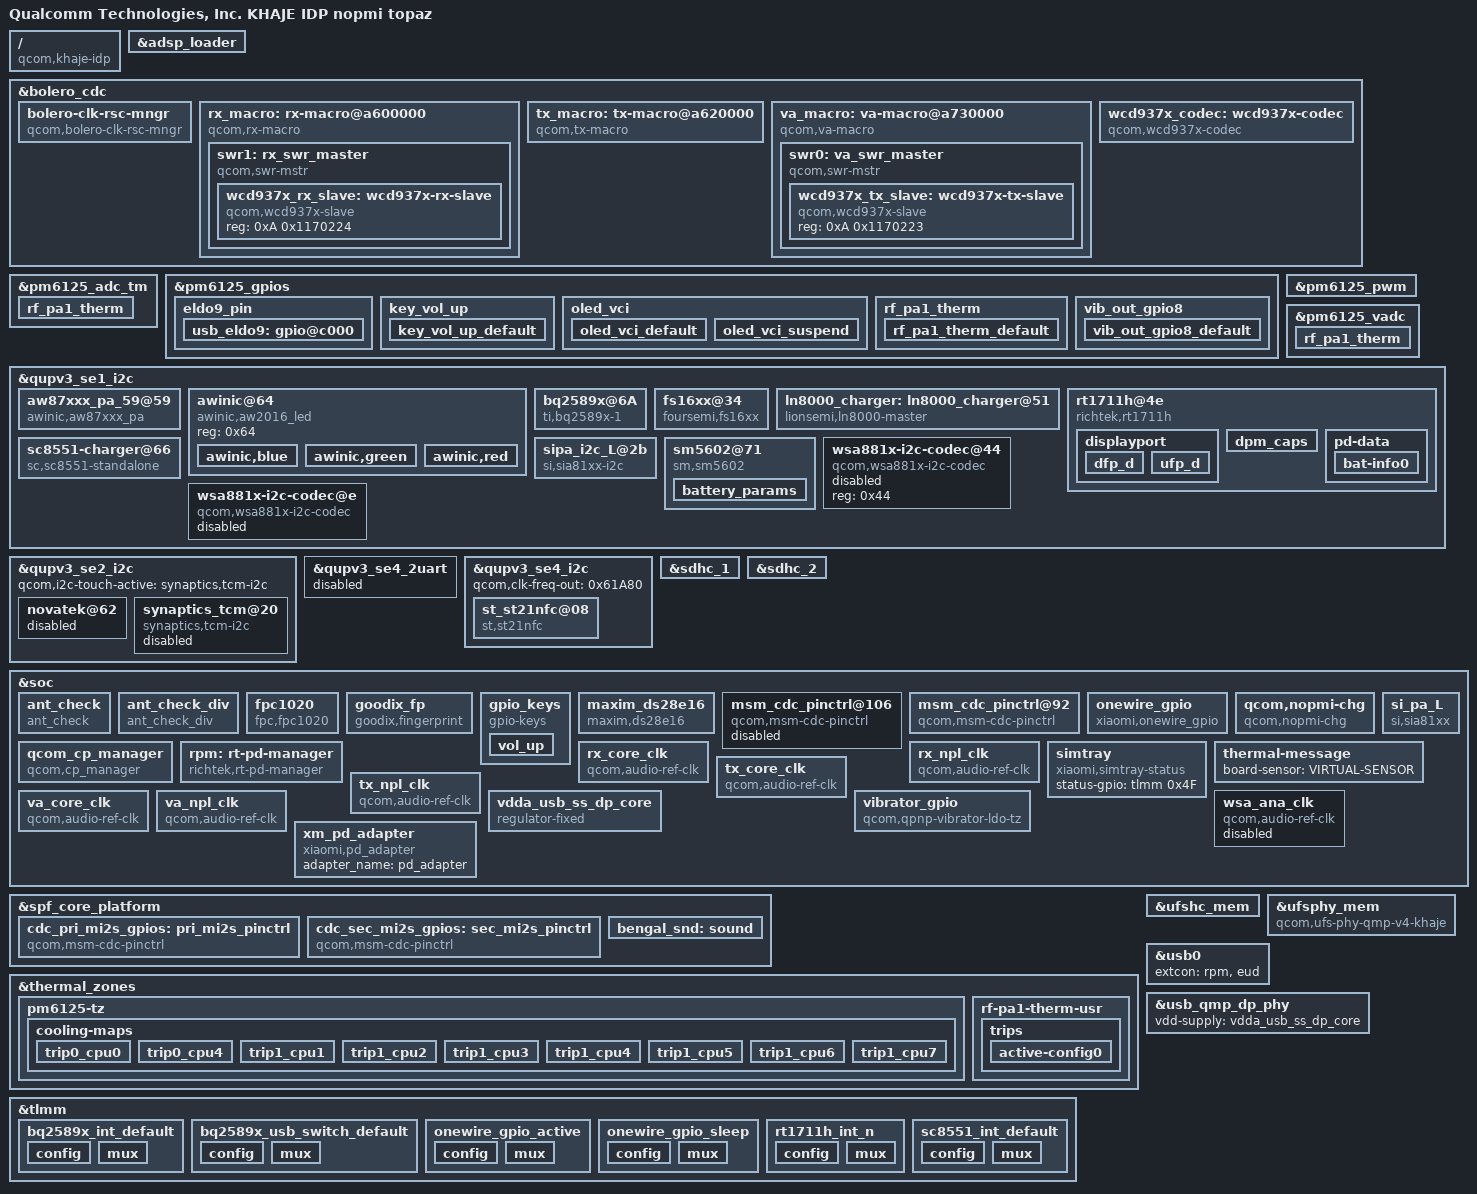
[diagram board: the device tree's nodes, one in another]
/dts-v1/;
// version: 17
// last_comp_version: 16
// boot_cpuid_phys: 0x0

/ {
    compatible = "qcom,khaje-idp", "qcom,khaje", "qcom,idp";
    model = "Qualcomm Technologies, Inc. KHAJE IDP nopmi topaz";
    qcom,board-id = <0x30022 0x0>;
    qcom,msm-id = <0x24A 0x10000>;
    qcom,pmic-id = <0x2D 0x0 0x0 0x0>;
};

&adsp_loader {
    adsp-fw-bit-values = <0x1>;
    adsp-fw-names = "adsp2";
    nvmem-cell-names = "adsp_variant";
    nvmem-cells = <&adsp_variant>;
};

&bolero_cdc {
    qcom,bolero-version = <0x5>;
    qcom,num-macros = <0x3>;
    bolero-clk-rsc-mngr {
        clock-names = "tx_core_clk", "tx_npl_clk", "rx_core_clk", "rx_npl_clk", "va_core_clk", "va_npl_clk";
        clocks = <&clock_audio_tx_1 0x0 &clock_audio_tx_2 0x0 &clock_audio_rx_1 0x0 &clock_audio_rx_2 0x0 &clock_audio_va_1 0x0 &clock_audio_va_2 0x0>;
        compatible = "qcom,bolero-clk-rsc-mngr";
        qcom,fs-gen-sequence = <0x3000 0x1 0x1 0x3004 0x3 0x3 0x3004 0x3 0x1 0x3080 0x2 0x2>;
        qcom,rx_mclk_mode_muxsel = <0xA5640D8>;
        qcom,va_mclk_mode_muxsel = <0xA7A0000>;
    };
    rx_macro: rx-macro@a600000 {
        clock-names = "rx_core_clk", "rx_npl_clk";
        clocks = <&clock_audio_rx_1 0x0 &clock_audio_rx_2 0x0>;
        compatible = "qcom,rx-macro";
        qcom,default-clk-id = <0x0>;
        qcom,rx-bcl-pmic-params = [00 04 3E];
        qcom,rx-swr-gpios = <&rx_swr_gpios>;
        qcom,rx_mclk_mode_muxsel = <0xA5640D8>;
        reg = <0xA600000 0x0>;
        swr1: rx_swr_master {
            #address-cells = <0x2>;
            #size-cells = <0x0>;
            clock-names = "lpass_audio_hw_vote";
            clocks = <&lpass_audio_hw_vote 0x0>;
            compatible = "qcom,swr-mstr";
            interrupt-names = "swr_master_irq";
            interrupts = <0x0 0x129 0x4>;
            qcom,disable-div2-clk-switch = <0x1>;
            qcom,mipi-sdw-block-packing-mode = <0x1>;
            qcom,swr-clock-stop-mode0 = <0x1>;
            qcom,swr-master-version = <0x1060000>;
            qcom,swr-num-dev = <0x1>;
            qcom,swr-num-ports = <0x5>;
            qcom,swr-port-mapping = <0x1 0xE 0x1 0x1 0xF 0x2 0x2 0x12 0x1 0x3 0x10 0x1 0x3 0x11 0x2 0x4 0x13 0x1 0x5 0x14 0x1 0x5 0x15 0x2>;
            qcom,swr_master_id = <0x2>;
            qcom,swrm-hctl-reg = <0xA6A9098>;
            swrm-io-base = <0xA610000 0x0>;
            wcd937x_rx_slave: wcd937x-rx-slave {
                compatible = "qcom,wcd937x-slave";
                reg = <0xA 0x1170224>;
            };
        };
    };
    tx_macro: tx-macro@a620000 {
        clock-names = "tx_core_clk", "tx_npl_clk";
        clocks = <&clock_audio_tx_1 0x0 &clock_audio_tx_2 0x0>;
        compatible = "qcom,tx-macro";
        qcom,is-used-swr-gpio = <0x0>;
        qcom,tx-dmic-sample-rate = <0x249F00>;
        reg = <0xA620000 0x0>;
    };
    va_macro: va-macro@a730000 {
        clock-names = "lpass_audio_hw_vote";
        clocks = <&lpass_audio_hw_vote 0x0>;
        compatible = "qcom,va-macro";
        qcom,default-clk-id = <0x0>;
        qcom,is-used-swr-gpio = <0x1>;
        qcom,va-clk-mux-select = <0x1>;
        qcom,va-dmic-sample-rate = <0x927C0>;
        qcom,va-island-mode-muxsel = <0xA7A0000>;
        qcom,va-swr-gpios = <&va_swr_gpios>;
        reg = <0xA730000 0x0>;
        swr0: va_swr_master {
            #address-cells = <0x2>;
            #size-cells = <0x0>;
            clock-names = "lpass_audio_hw_vote";
            clocks = <&lpass_audio_hw_vote 0x0>;
            compatible = "qcom,swr-mstr";
            interrupt-names = "swr_master_irq", "swr_wake_irq";
            interrupts = <0x0 0x128 0x4 0x0 0x4F 0x4>;
            qcom,is-always-on = <0x1>;
            qcom,mipi-sdw-block-packing-mode = <0x1>;
            qcom,swr-clock-stop-mode0 = <0x1>;
            qcom,swr-master-version = <0x1060000>;
            qcom,swr-mstr-irq-wakeup-capable = <0x1>;
            qcom,swr-num-dev = <0x1>;
            qcom,swr-num-ports = <0x3>;
            qcom,swr-port-mapping = <0x1 0x2E 0x1 0x1 0x2F 0x2 0x1 0x30 0x4 0x1 0x31 0x8 0x2 0x32 0x1 0x2 0x33 0x2 0x2 0x34 0x4 0x2 0x35 0x8 0x3 0x36 0x1 0x3 0x37 0x2 0x3 0x38 0x4 0x3 0x39 0x8>;
            qcom,swr-wakeup-required = <0x1>;
            qcom,swr_master_id = <0x3>;
            qcom,swrm-hctl-reg = <0xA7EC100>;
            swrm-io-base = <0xA740000 0x0>;
            wcd937x_tx_slave: wcd937x-tx-slave {
                compatible = "qcom,wcd937x-slave";
                reg = <0xA 0x1170223>;
            };
        };
    };
    wcd937x_codec: wcd937x-codec {
        cdc-vdd-buck-supply = <&L14A>;
        cdc-vdd-rxtx-supply = <&L9A>;
        cdc-vddpx-supply = <&L9A>;
        compatible = "qcom,wcd937x-codec";
        qcom,cdc-micbias1-mv = <0xA8C>;
        qcom,cdc-micbias2-mv = <0xA8C>;
        qcom,cdc-micbias3-mv = <0xA8C>;
        qcom,cdc-on-demand-supplies = "cdc-vdd-buck";
        qcom,cdc-static-supplies = "cdc-vdd-rxtx", "cdc-vddpx";
        qcom,cdc-vdd-buck-current = <0x9EB10>;
        qcom,cdc-vdd-buck-voltage = <0x1B7740 0x1B7740>;
        qcom,cdc-vdd-rxtx-current = <0x2710>;
        qcom,cdc-vdd-rxtx-voltage = <0x1B7740 0x1B7740>;
        qcom,cdc-vddpx-current = <0x4E20>;
        qcom,cdc-vddpx-voltage = <0x1B7740 0x1B7740>;
        qcom,rx-slave = <&wcd937x_rx_slave>;
        qcom,rx_swr_ch_map = <0x0 0xE 0x1 0x0 0xE 0x0 0xF 0x2 0x0 0xF 0x1 0x12 0x1 0x0 0x12 0x2 0x10 0x1 0x0 0x10 0x2 0x11 0x2 0x0 0x11 0x3 0x13 0x1 0x0 0x13 0x4 0x14 0x1 0x0 0x14 0x4 0x15 0x2 0x0 0x15>;
        qcom,split-codec = <0x1>;
        qcom,swr-tx-port-params = <0x1 0x0 0x0 0x1 0x1 0x0 0x1 0x0 0x0 0x1 0x1 0x0 0x1 0x0 0x1 0x0 0x0 0x1 0x2 0x0 0x1 0x0 0x2 0x0 0x1 0x0 0x1 0x0 0x1 0x0 0x1 0x0>;
        qcom,tx-slave = <&wcd937x_tx_slave>;
        qcom,tx_swr_ch_map = <0x0 0x1E 0x1 0x493E00 0x2E 0x1 0x1F 0x1 0x493E00 0x32 0x1 0x20 0x2 0x493E00 0x33 0x2 0x22 0x1 0x0 0x31 0x2 0x23 0x2 0x0 0x32 0x2 0x1D 0x4 0x493E00 0x33 0x3 0x24 0x1 0x0 0x34 0x3 0x25 0x2 0x0 0x35 0x3 0x26 0x4 0x0 0x36 0x3 0x27 0x8 0x0 0x37>;
        qcom,wcd-rst-gpio-node = <&wcd937x_rst_gpio>;
    };
};

&pm6125_adc_tm {
    status = "ok";
    rf_pa1_therm {
        io-channels = <&pm6125_vadc 0x55>;
        qcom,hw-settle-time-us = <0xC8>;
        qcom,ratiometric;
        reg = <0x3>;
    };
};

&pm6125_gpios {
    eldo9_pin {
        usb_eldo9: gpio@c000 {
            bias-disable;
            function = "normal";
            output-high;
            pins = "gpio1";
            power-source = <0x0>;
            qcom,drive-strength = <0x2>;
        };
    };
    key_vol_up {
        key_vol_up_default: key_vol_up_default {
            bias-pull-up;
            function = "normal";
            input-enable;
            pins = "gpio5";
            power-source = <0x0>;
        };
    };
    oled_vci {
        oled_vci_default: oled_vci_default {
            bias-disable;
            function = "normal";
            input-disable;
            output-high;
            pins = "gpio9";
            power-source = <0x0>;
            qcom,drive-strength = <0x2>;
        };
        oled_vci_suspend: oled_vci_suspend {
            bias-disable;
            function = "normal";
            input-disable;
            output-low;
            pins = "gpio9";
            power-source = <0x0>;
            qcom,drive-strength = <0x2>;
        };
    };
    rf_pa1_therm {
        rf_pa1_therm_default: rf_pa1_therm_default {
            bias-high-impedance;
            pins = "gpio7";
        };
    };
    vib_out_gpio8 {
        vib_out_gpio8_default: vib_out_gpio8_default {
            bias-pull-up;
            function = "normal";
            pins = "gpio8";
            power-source = <0x0>;
        };
    };
};

&pm6125_pwm {
    status = "ok";
};

&pm6125_vadc {
    pinctrl-0 = <&camera_therm_default &emmc_therm_default &rf_pa1_therm_default>;
    rf_pa1_therm {
        label = "rf_pa1_therm";
        qcom,hw-settle-time = <0xC8>;
        qcom,pre-scaling = <0x1 0x1>;
        qcom,ratiometric;
        reg = <0x55>;
    };
};

&qupv3_se1_i2c {
    #address-cells = <0x1>;
    #size-cells = <0x0>;
    status = "ok";
    aw87xxx_pa_59@59 {
        aw-rx-port-id = <0xB032>;
        compatible = "awinic,aw87xxx_pa";
        dev_index = <0x0>;
        reg = <0x59>;
        reset-gpio = <&tlmm 0x6A 0x0>;
        status = "okay";
    };
    awinic@64 {
        compatible = "awinic,aw2016_led";
        reg = <0x64>;
        awinic,blue {
            awinic,fall-time-ms = <0x6>;
            awinic,hold-time-ms = <0x0>;
            awinic,id = <0x2>;
            awinic,imax = <0x2>;
            awinic,led-current = <0x3>;
            awinic,max-brightness = <0xFF>;
            awinic,name = "blue";
            awinic,off-time-ms = <0x4>;
            awinic,rise-time-ms = <0x6>;
        };
        awinic,green {
            awinic,fall-time-ms = <0x6>;
            awinic,hold-time-ms = <0x0>;
            awinic,id = <0x1>;
            awinic,imax = <0x2>;
            awinic,led-current = <0x3>;
            awinic,max-brightness = <0xFF>;
            awinic,name = "green";
            awinic,off-time-ms = <0x4>;
            awinic,rise-time-ms = <0x6>;
        };
        awinic,red {
            awinic,fall-time-ms = <0x6>;
            awinic,hold-time-ms = <0x0>;
            awinic,id = <0x0>;
            awinic,imax = <0x2>;
            awinic,led-current = <0x3>;
            awinic,max-brightness = <0xFF>;
            awinic,name = "red";
            awinic,off-time-ms = <0x4>;
            awinic,rise-time-ms = <0x6>;
        };
    };
    bq2589x@6A {
        #address-cells = <0x1>;
        #io-channel-cells = <0x1>;
        #size-cells = <0x0>;
        compatible = "ti,bq2589x-1";
        interrupt-parent = <&tlmm>;
        interrupts = <0x69 0x0>;
        intr-gpio = <&tlmm 0x69 0x0>;
        io-channel-names = "ds_chip_ok", "fastcharge_mode", "fg_monitor_work", "mtbf_cur", "usb_real_type", "pd_active", "typec_cc_orientation", "typec_mode", "ffc_disable";
        io-channels = <&maxim_ds28e16 0x8B &sm5602 0xA2 &sm5602 0xB0 &nopmi_chg 0x8E &nopmi_chg 0xA &nopmi_chg 0x4 &nopmi_chg 0x3 &nopmi_chg 0x1 &nopmi_chg 0xAF>;
        pinctrl-0 = <&bq2589x_int_default &bq2589x_usb_switch_default>;
        pinctrl-names = "default";
        reg = <0x6A>;
        ti,bq2589x,charge-current = <0x7D0>;
        ti,bq2589x,charge-current-1000 = <0x3E8>;
        ti,bq2589x,charge-current-1500 = <0x5DC>;
        ti,bq2589x,charge-current-3500 = <0xDAC>;
        ti,bq2589x,charge-current-500 = <0x1F4>;
        ti,bq2589x,charge-voltage = <0x1162>;
        ti,bq2589x,enable-auto-dpdm;
        ti,bq2589x,enable-ico;
        ti,bq2589x,enable-termination;
        ti,bq2589x,input-current-2000 = <0x7D0>;
        ti,bq2589x,term-current = <0x100>;
        ti,bq2589x,use-absolute-vindpm;
        ti,bq2589x,vbat-min-volt-to-tuneup = <0xBB8>;
        ti,bq2589x,vbus-volt-high-level = <0x21FC>;
        ti,bq2589x,vbus-volt-low-level = <0x1130>;
        usb-switch1 = <&tlmm 0x42 0x0>;
    };
    fs16xx@34 {
        compatible = "foursemi,fs16xx";
        fsm,rst-gpio = <&tlmm 0x6A 0x0>;
        reg = <0x34>;
        status = "okay";
    };
    ln8000_charger: ln8000_charger@51 {
        #io-channel-cells = <0x1>;
        compatible = "lionsemi,ln8000-master";
        irq-gpios = <&tlmm 0x54 0x0>;
        ln8000_charger,bat-ovp-alarm-threshold = <0x11AD>;
        ln8000_charger,bat-ovp-threshold = <0x11C6>;
        ln8000_charger,bus-ocp-alarm-threshold = <0xDAC>;
        ln8000_charger,bus-ocp-threshold = <0xEA6>;
        ln8000_charger,bus-ovp-alarm-threshold = <0x2AF8>;
        ln8000_charger,bus-ovp-threshold = <0x32C8>;
        ln8000_charger,ext_ovp_ctrl = <0x0>;
        ln8000_charger,ntc-alarm-cfg = <0xE2>;
        ln8000_charger,tbat-mon-disable;
        ln8000_charger,tbus-mon-disable;
        ln8000_charger,tdie-prot-disable;
        reg = <0x51>;
    };
    rt1711h@4e {
        #io-channel-cells = <0x1>;
        compatible = "richtek,rt1711h";
        pinctrl-0 = <&rt1711h_int_n>;
        pinctrl-names = "default";
        reg = <0x4E>;
        rt-tcpc,name = "type_c_port0";
        rt-tcpc,role_def = <0x5>;
        rt-tcpc,rp_level = <0x1>;
        rt-tcpc,vconn_supply = <0x1>;
        rt1711pd,intr_gpio = <&tlmm 0x5D 0x0>;
        rt1711pd,intr_gpio_num = <0x5D>;
        status = "okay";
        tcpc-dual,supported_modes = <0x0>;
        displayport {
            1st_connection = "dfp_d";
            2nd_connection = "dfp_d";
            signal,dp_v13;
            typec,receptacle;
            dfp_d {
                pin_assignment,mode_c;
                pin_assignment,mode_d;
                pin_assignment,mode_e;
            };
            ufp_d {
            };
        };
        dpm_caps {
            attempt_discover_cable;
            attempt_discover_id;
            attempt_enter_dp_mode;
            dr_check = <0x0>;
            local_dr_data;
            local_dr_power;
            local_no_suspend;
            local_usb_comm;
            local_vconn_supply;
            pr_check = <0x0>;
        };
        pd-data {
            bat,nr = <0x1>;
            pd,charging_policy = <0x31>;
            pd,country_nr = <0x0>;
            pd,id-vdo-data = <0xD14029CF 0x0 0x17110000 0x61000000 0x0 0x41000000>;
            pd,id-vdo-size = <0x6>;
            pd,mfrs = "RichtekTCPC";
            pd,pid = <0x1711>;
            pd,sink-pdo-data = <0x190C8>;
            pd,sink-pdo-size = <0x1>;
            pd,source-cap-ext = [CF 29 11 17 00 00 00 00 00 00 00 00 00 00 00 00 00 00 00 00 00 00 01 02 00];
            pd,source-pdo-data = <0x19032>;
            pd,source-pdo-size = <0x1>;
            pd,vid = <0x29CF>;
            bat-info0 {
                bat,design_cap = <0xBB8>;
                bat,mfrs = "bat1";
                bat,pid = <0x1711>;
                bat,vid = <0x29CF>;
            };
        };
    };
    sc8551-charger@66 {
        #io-channel-cells = <0x1>;
        compatible = "sc,sc8551-standalone";
        irq-gpios = <&tlmm 0x54 0x0>;
        reg = <0x66>;
        sc,sc8551,ac-ovp-threshold = <0xC>;
        sc,sc8551,bat-ocp-alarm-threshold = <0x1D4C>;
        sc,sc8551,bat-ocp-threshold = <0x1F40>;
        sc,sc8551,bat-ovp-alarm-threshold = <0x1130>;
        sc,sc8551,bat-ovp-threshold = <0x11AD>;
        sc,sc8551,bat-therm-disable = <0x0>;
        sc,sc8551,bat-therm-threshold = <0x15>;
        sc,sc8551,bat-ucp-alarm-threshold = <0x7D0>;
        sc,sc8551,bus-ocp-alarm-threshold = <0xDAC>;
        sc,sc8551,bus-ocp-threshold = <0xEA6>;
        sc,sc8551,bus-ovp-alarm-threshold = <0x2AF8>;
        sc,sc8551,bus-ovp-threshold = <0x2EE0>;
        sc,sc8551,bus-therm-disable = <0x0>;
        sc,sc8551,bus-therm-threshold = <0x15>;
        sc,sc8551,die-therm-threshold = <0x7D>;
        sc,sc8551,sense-resistor-mohm = <0x5>;
    };
    sipa_i2c_L@2b {
        compatible = "si,sia81xx-i2c";
        reg = <0x2B>;
        si,sipa-dev = <&si_pa_L>;
    };
    sm5602@71 {
        #io-channel-cells = <0x1>;
        compatible = "sm,sm5602";
        io-channel-names = "ds_authen_result", "ds_romid", "ds_status", "ds_page0_data", "ds_chip_ok", "usb_real_type", "charging_enabled", "sc_battery_voltage", "ln_charging_enabled", "ln_battery_voltage", "charge_done";
        io-channels = <&maxim_ds28e16 0x82 &maxim_ds28e16 0x7E &maxim_ds28e16 0x7F &maxim_ds28e16 0x88 &maxim_ds28e16 0x8B &nopmi_chg 0xA &sc8551_standalone 0x76 &sc8551_standalone 0x94 &ln8000_charger 0x76 &ln8000_charger 0x94 &bq2589x 0x39>;
        reg = <0x71>;
        sm,aging_ctrl = <0x121>;
        sm,battery_table_num = <0x0>;
        sm,cycle_cfg = <0x7000>;
        sm,en_batt_det;
        sm,en_temp_ex;
        sm,fg_irq_set = <0x7FF>;
        sm,iocv_man_mode;
        sm,low_soc1 = <0x1>;
        sm,low_soc2 = <0xF>;
        sm,misc = <0x800>;
        sm,param_version = <0x5>;
        sm,rsns = <0x0>;
        sm,rtrace = <0x7D0>;
        sm,shutdown-delay-enable;
        sm,soc_decimal_rate = <0x0 0x26 0xA 0x23 0x14 0x21 0x1E 0x21 0x28 0x21 0x32 0x21 0x3C 0x21 0x46 0x1E 0x50 0x19 0x5A 0x14 0x5F 0xA>;
        sm,t_h_alarm_ex = <0x9245>;
        sm,t_h_alarm_in = <0x1>;
        sm,t_l_alarm_ex = <0xD3D8>;
        sm,t_l_alarm_in = <0x36>;
        sm,v_h_alarm = <0x9245>;
        sm,v_l_alarm = <0xD3D8>;
        battery_params {
            battery0,alpha = <0xCC>;
            battery0,battery_table0 = <0x1400 0x1B3D 0x1C5E 0x1D3A 0x1D80 0x1D8D 0x1D93 0x1DAA 0x1DFA 0x1E3E 0x1E77 0x1EB2 0x1F09 0x1F67 0x1FB3 0x1FE6 0x2046 0x20EB 0x21A1 0x2220 0x227A 0x2319 0x2360 0x24CC>;
            battery0,battery_table1 = <0x0 0x68 0x1F2 0x400 0x58A 0x798 0xAAC 0xCBA 0x1367 0x1B1A 0x22CD 0x2A80 0x3234 0x3756 0x39E7 0x3C78 0x419A 0x494E 0x5101 0x5623 0x59BB 0x60EB 0x6400 0x64E6>;
            battery0,battery_table2 = <0x141C 0x1011 0xE0F 0xC0D 0xB0B 0xA0B 0xA0A 0x909>;
            battery0,battery_type = <0x1162 0x0 0x26C9>;
            battery0,beta = <0x25>;
            battery0,curr_offset = <0x0>;
            battery0,curr_slope = <0x8080>;
            battery0,ext_temp_cal = <0x0 0x2 0x1 0x2 0x1 0x1 0x2 0x3 0x2 0x3>;
            battery0,fcm_offset = <0x52>;
            battery0,max_voltage_uv = <0x43E6D0>;
            battery0,mix_value = <0x3>;
            battery0,param_version = <0x1>;
            battery0,rs = <0x5F>;
            battery0,rs_value = <0x50 0x10A 0x3800 0x48>;
            battery0,tem_poff = <0xD48 0x64>;
            battery0,temp_cal = <0x0 0x6 0x1 0xB 0xFFFFFFFF 0x0 0x6 0x1 0x9 0x1>;
            battery0,temp_offset = <0x0 0xB 0x1 0x0 0x8 0xFFFFFFFF>;
            battery0,temp_std = <0x19>;
            battery0,thermal_table = <0x506E 0x4F35 0x4E07 0x4CC0 0x4B76 0x4A25 0x48BD 0x475D 0x45F5 0x4477 0x4304 0x4175 0x3FDE 0x3E4A 0x3CA2 0x3AF6 0x3945 0x378A 0x35CB 0x33FC 0x322B 0x3059 0x2E82 0x2CA0 0x2AC6 0x28C6 0x26E0 0x24EA 0x22E8 0x20EF 0x1EE7 0x1CEE 0x1AE8 0x18D0 0x16D6 0x14CE 0x12F3 0x10E4 0xED6 0xCC4 0xABC 0x8BC 0x6A8 0x4AD 0x2A1 0x9E 0xF669 0xF471 0xF278 0xF081 0xEE7B 0xEC8C 0xEAA1 0xE8BE 0xE6E1 0xE505 0xE332 0xE162 0xDF9B 0xDDD9 0xDC1F 0xDA67 0xD8B4 0xD70B 0xD565 0xD3C7 0xD232 0xD0A1 0xCF18 0xCD94 0xCC18 0xCAA5 0xC936 0xC7D3 0xC670 0xC519 0xC3C6 0xC27A 0xC136 0xBFF7 0xBEC1 0xBD92 0xBC6E 0xBB4D 0xBA36 0xB922 0xB816 0xB712 0xB611 0xB517 0xB422 0xB334 0xB249 0xB164 0xB085 0xAFAD 0xAED8 0xAE0A 0xAD3E 0xAC78 0xABB7>;
            battery0,topoff_soc = <0x7 0x12C 0x64>;
            battery0,vit_period = <0x315A>;
            battery0,volt_cal = <0x8000>;
            battery1,alpha = <0xCC>;
            battery1,battery_table0 = <0x1400 0x1B35 0x1C26 0x1CEC 0x1D66 0x1D8C 0x1D97 0x1DB6 0x1E00 0x1E48 0x1E7D 0x1EBD 0x1F12 0x1F70 0x1FBD 0x1FED 0x2050 0x20F3 0x21A7 0x2224 0x227B 0x2317 0x235B 0x24CC>;
            battery1,battery_table1 = <0x0 0x66 0x193 0x31B 0x4A3 0x730 0xB44 0xD4E 0x13EF 0x1B96 0x233C 0x2AE2 0x3288 0x37A2 0x3A2E 0x3CBB 0x41D5 0x497B 0x5121 0x563B 0x59CC 0x60F0 0x6400 0x64E6>;
            battery1,battery_table2 = <0x1720 0x1214 0x1011 0xD0E 0xC0C 0xB0B 0xA0A 0xA0A>;
            battery1,battery_type = <0x1162 0x0 0x2700>;
            battery1,beta = <0x25>;
            battery1,curr_offset = <0x0>;
            battery1,curr_slope = <0x8080>;
            battery1,ext_temp_cal = <0x0 0x2 0x1 0x2 0x1 0x1 0x2 0x3 0x2 0x3>;
            battery1,fcm_offset = <0x67>;
            battery1,max_voltage_uv = <0x43E6D0>;
            battery1,mix_value = <0x3>;
            battery1,param_version = <0x2>;
            battery1,rs = <0x5F>;
            battery1,rs_value = <0x50 0x10A 0x3800 0x48>;
            battery1,tem_poff = <0xD48 0x64>;
            battery1,temp_cal = <0x0 0x6 0x1 0xB 0xFFFFFFFF 0x0 0x6 0x1 0x9 0x1>;
            battery1,temp_offset = <0x0 0xB 0x1 0x0 0x8 0xFFFFFFFF>;
            battery1,temp_std = <0x19>;
            battery1,thermal_table = <0x506E 0x4F35 0x4E07 0x4CC0 0x4B76 0x4A25 0x48BD 0x475D 0x45F5 0x4477 0x4304 0x4175 0x3FDE 0x3E4A 0x3CA2 0x3AF6 0x3945 0x378A 0x35CB 0x33FC 0x322B 0x3059 0x2E82 0x2CA0 0x2AC6 0x28C6 0x26E0 0x24EA 0x22E8 0x20EF 0x1EE7 0x1CEE 0x1AE8 0x18D0 0x16D6 0x14CE 0x12F3 0x10E4 0xED6 0xCC4 0xABC 0x8BC 0x6A8 0x4AD 0x2A1 0x9E 0xF669 0xF471 0xF278 0xF081 0xEE7B 0xEC8C 0xEAA1 0xE8BE 0xE6E1 0xE505 0xE332 0xE162 0xDF9B 0xDDD9 0xDC1F 0xDA67 0xD8B4 0xD70B 0xD565 0xD3C7 0xD232 0xD0A1 0xCF18 0xCD94 0xCC18 0xCAA5 0xC936 0xC7D3 0xC670 0xC519 0xC3C6 0xC27A 0xC136 0xBFF7 0xBEC1 0xBD92 0xBC6E 0xBB4D 0xBA36 0xB922 0xB816 0xB712 0xB611 0xB517 0xB422 0xB334 0xB249 0xB164 0xB085 0xAFAD 0xAED8 0xAE0A 0xAD3E 0xAC78 0xABB7>;
            battery1,topoff_soc = <0x7 0x12C 0x64>;
            battery1,vit_period = <0x315A>;
            battery1,volt_cal = <0x8000>;
            battery2,alpha = <0xCC>;
            battery2,battery_table0 = <0x1400 0x1B3D 0x1C5E 0x1D3A 0x1D80 0x1D8D 0x1D93 0x1DAA 0x1DFA 0x1E3E 0x1E77 0x1EB2 0x1F09 0x1F67 0x1FB3 0x1FE6 0x2046 0x20EB 0x21A1 0x2220 0x227A 0x2319 0x2360 0x24CC>;
            battery2,battery_table1 = <0x0 0x68 0x1F2 0x400 0x58A 0x798 0xAAC 0xCBA 0x1367 0x1B1A 0x22CD 0x2A80 0x3234 0x3756 0x39E7 0x3C78 0x419A 0x494E 0x5101 0x5623 0x59BB 0x60EB 0x6400 0x64E6>;
            battery2,battery_table2 = <0x141C 0x1011 0xE0F 0xC0D 0xB0B 0xA0B 0xA0A 0x909>;
            battery2,battery_type = <0x1162 0x0 0x26C9>;
            battery2,beta = <0x25>;
            battery2,curr_offset = <0x0>;
            battery2,curr_slope = <0x8080>;
            battery2,ext_temp_cal = <0x0 0x2 0x1 0x2 0x1 0x1 0x2 0x3 0x2 0x3>;
            battery2,fcm_offset = <0x52>;
            battery2,max_voltage_uv = <0x43E6D0>;
            battery2,mix_value = <0x3>;
            battery2,param_version = <0x1>;
            battery2,rs = <0x5F>;
            battery2,rs_value = <0x50 0x10A 0x3800 0x48>;
            battery2,tem_poff = <0xD48 0x64>;
            battery2,temp_cal = <0x0 0x6 0x1 0xB 0xFFFFFFFF 0x0 0x6 0x1 0x9 0x1>;
            battery2,temp_offset = <0x0 0xB 0x1 0x0 0x8 0xFFFFFFFF>;
            battery2,temp_std = <0x19>;
            battery2,thermal_table = <0x506E 0x4F35 0x4E07 0x4CC0 0x4B76 0x4A25 0x48BD 0x475D 0x45F5 0x4477 0x4304 0x4175 0x3FDE 0x3E4A 0x3CA2 0x3AF6 0x3945 0x378A 0x35CB 0x33FC 0x322B 0x3059 0x2E82 0x2CA0 0x2AC6 0x28C6 0x26E0 0x24EA 0x22E8 0x20EF 0x1EE7 0x1CEE 0x1AE8 0x18D0 0x16D6 0x14CE 0x12F3 0x10E4 0xED6 0xCC4 0xABC 0x8BC 0x6A8 0x4AD 0x2A1 0x9E 0xF669 0xF471 0xF278 0xF081 0xEE7B 0xEC8C 0xEAA1 0xE8BE 0xE6E1 0xE505 0xE332 0xE162 0xDF9B 0xDDD9 0xDC1F 0xDA67 0xD8B4 0xD70B 0xD565 0xD3C7 0xD232 0xD0A1 0xCF18 0xCD94 0xCC18 0xCAA5 0xC936 0xC7D3 0xC670 0xC519 0xC3C6 0xC27A 0xC136 0xBFF7 0xBEC1 0xBD92 0xBC6E 0xBB4D 0xBA36 0xB922 0xB816 0xB712 0xB611 0xB517 0xB422 0xB334 0xB249 0xB164 0xB085 0xAFAD 0xAED8 0xAE0A 0xAD3E 0xAC78 0xABB7>;
            battery2,topoff_soc = <0x7 0x12C 0x64>;
            battery2,vit_period = <0x315A>;
            battery2,volt_cal = <0x8000>;
            battery3,alpha = <0xCC>;
            battery3,battery_table0 = <0x1400 0x1B32 0x1BFD 0x1CD9 0x1D76 0x1D8C 0x1D96 0x1DB5 0x1DFE 0x1E43 0x1E75 0x1EB2 0x1F06 0x1F6C 0x1FB4 0x1FE2 0x2041 0x20E5 0x219C 0x221B 0x2274 0x2315 0x2361 0x24CC>;
            battery3,battery_table1 = <0x0 0x66 0x149 0x2D1 0x4DD 0x6E9 0xB01 0xD0C 0x13B2 0x1B5F 0x230B 0x2AB7 0x3263 0x3780 0x3A0F 0x3C9D 0x41BB 0x4967 0x5113 0x5630 0x59C5 0x60EE 0x6400 0x64E6>;
            battery3,battery_table2 = <0x131B 0xF11 0xE0E 0xC0C 0xB0B 0xA0A 0x90A 0x909>;
            battery3,battery_type = <0x1162 0x0 0x26CC>;
            battery3,beta = <0x25>;
            battery3,curr_offset = <0x0>;
            battery3,curr_slope = <0x8080>;
            battery3,ext_temp_cal = <0x0 0x2 0x1 0x2 0x1 0x1 0x2 0x3 0x2 0x3>;
            battery3,fcm_offset = <0x67>;
            battery3,max_voltage_uv = <0x43E6D0>;
            battery3,mix_value = <0x3>;
            battery3,param_version = <0x1>;
            battery3,rs = <0x5F>;
            battery3,rs_value = <0x50 0x10A 0x3800 0x48>;
            battery3,tem_poff = <0xD48 0x64>;
            battery3,temp_cal = <0x0 0x6 0x1 0xB 0xFFFFFFFF 0x0 0x6 0x1 0x9 0x1>;
            battery3,temp_offset = <0x0 0xB 0x1 0x0 0x8 0xFFFFFFFF>;
            battery3,temp_std = <0x19>;
            battery3,thermal_table = <0x506E 0x4F35 0x4E07 0x4CC0 0x4B76 0x4A25 0x48BD 0x475D 0x45F5 0x4477 0x4304 0x4175 0x3FDE 0x3E4A 0x3CA2 0x3AF6 0x3945 0x378A 0x35CB 0x33FC 0x322B 0x3059 0x2E82 0x2CA0 0x2AC6 0x28C6 0x26E0 0x24EA 0x22E8 0x20EF 0x1EE7 0x1CEE 0x1AE8 0x18D0 0x16D6 0x14CE 0x12F3 0x10E4 0xED6 0xCC4 0xABC 0x8BC 0x6A8 0x4AD 0x2A1 0x9E 0xF669 0xF471 0xF278 0xF081 0xEE7B 0xEC8C 0xEAA1 0xE8BE 0xE6E1 0xE505 0xE332 0xE162 0xDF9B 0xDDD9 0xDC1F 0xDA67 0xD8B4 0xD70B 0xD565 0xD3C7 0xD232 0xD0A1 0xCF18 0xCD94 0xCC18 0xCAA5 0xC936 0xC7D3 0xC670 0xC519 0xC3C6 0xC27A 0xC136 0xBFF7 0xBEC1 0xBD92 0xBC6E 0xBB4D 0xBA36 0xB922 0xB816 0xB712 0xB611 0xB517 0xB422 0xB334 0xB249 0xB164 0xB085 0xAFAD 0xAED8 0xAE0A 0xAD3E 0xAC78 0xABB7>;
            battery3,topoff_soc = <0x7 0x12C 0x64>;
            battery3,vit_period = <0x315A>;
            battery3,volt_cal = <0x8000>;
        };
    };
    wsa881x-i2c-codec@44 {
        compatible = "qcom,wsa881x-i2c-codec";
        reg = <0x44>;
        status = "disable";
    };
    wsa881x-i2c-codec@e {
        clock-names = "wsa_mclk";
        clocks = <&wsa881x_analog_clk 0x0>;
        compatible = "qcom,wsa881x-i2c-codec";
        qcom,wsa-analog-clk-gpio = <&wsa881x_analog_clk_gpio>;
        qcom,wsa-analog-reset-gpio = <&wsa881x_analog_reset_gpio>;
        qcom,wsa-prefix = "SpkrMono";
        reg = <0xE>;
        status = "disable";
    };
};

&qupv3_se2_i2c {
    qcom,i2c-touch-active = "synaptics,tcm-i2c";
    status = "okay";
    novatek@62 {
        interrupt-parent = <&tlmm>;
        interrupts = <0x50 0x2008>;
        novatek,irq-gpio = <&tlmm 0x50 0x2008>;
        novatek,reset-gpio = <&tlmm 0x56 0x0>;
        pinctrl-0 = <&ts_int_active &ts_reset_active>;
        pinctrl-1 = <&ts_int_suspend &ts_reset_suspend>;
        pinctrl-2 = <&ts_release>;
        pinctrl-names = "pmx_ts_active", "pmx_ts_suspend", "pmx_ts_release";
        reg = <0x62>;
        status = "disabled";
    };
    synaptics_tcm@20 {
        compatible = "synaptics,tcm-i2c";
        interrupt-parent = <&tlmm>;
        interrupts = <0x50 0x2008>;
        pinctrl-0 = <&ts_int_active &ts_reset_active>;
        pinctrl-1 = <&ts_int_suspend &ts_reset_suspend>;
        pinctrl-2 = <&ts_release>;
        pinctrl-names = "pmx_ts_active", "pmx_ts_suspend", "pmx_ts_release";
        reg = <0x20>;
        status = "disable";
        synaptics,extend_report;
        synaptics,firmware-name = "synaptics_firmware_k.img";
        synaptics,irq-gpio = <&tlmm 0x50 0x2008>;
        synaptics,irq-on-state = <0x0>;
        synaptics,power-delay-ms = <0xC8>;
        synaptics,reset-active-ms = <0x14>;
        synaptics,reset-delay-ms = <0xC8>;
        synaptics,reset-gpio = <&tlmm 0x56 0x0>;
        synaptics,reset-on-state = <0x0>;
        synaptics,ubl-i2c-addr = <0x20>;
    };
};

&qupv3_se4_2uart {
    status = "disabled";
};

&qupv3_se4_i2c {
    #address-cells = <0x1>;
    #size-cells = <0x0>;
    qcom,clk-freq-out = <0x61A80>;
    status = "ok";
    st_st21nfc@08 {
        clock-names = "nfc_ref_clk";
        compatible = "st,st21nfc";
        interrupt-names = "nfc_irq";
        interrupt-parent = <&tlmm>;
        interrupts = <0x46 0x0>;
        reg = <0x8>;
        st,clk_pinctrl;
        st,clkreq-gpio = <&tlmm 0x47 0x0>;
        st,irq-gpio = <&tlmm 0x46 0x0>;
        st,reset-gpio = <&tlmm 0x45 0x0>;
    };
};

&sdhc_1 {
    pinctrl-0 = <&sdc1_on>;
    pinctrl-1 = <&sdc1_off>;
    pinctrl-names = "default", "sleep";
    qcom,vdd-current-level = <0x0 0x8B290>;
    qcom,vdd-io-always-on;
    qcom,vdd-io-current-level = <0x0 0x4F588>;
    qcom,vdd-io-lpm-sup;
    qcom,vdd-io-voltage-level = <0x1B7740 0x1B7740>;
    qcom,vdd-voltage-level = <0x2D2A80 0x2D2A80>;
    status = "ok";
    vdd-io-supply = <&L11A>;
    vdd-supply = <&L24A>;
};

&sdhc_2 {
    cd-gpios = <&tlmm 0x58 0x0>;
    pinctrl-0 = <&sdc2_on>;
    pinctrl-1 = <&sdc2_off>;
    pinctrl-names = "default", "sleep";
    qcom,vdd-current-level = <0x0 0xC3500>;
    qcom,vdd-io-bias-current-level = <0x0 0x1770>;
    qcom,vdd-io-bias-voltage-level = <0x132A40 0x132A40>;
    qcom,vdd-io-current-level = <0x0 0x55F0>;
    qcom,vdd-io-voltage-level = <0x1B7740 0x2D2A80>;
    qcom,vdd-voltage-level = <0x2D2A80 0x2D2A80>;
    status = "ok";
    vdd-io-bias-supply = <&L7A>;
    vdd-io-supply = <&L5A>;
    vdd-supply = <&L22A>;
};

&soc {
    ant_check {
        ant_check_gpio = <&tlmm 0x6B 0x0>;
        compatible = "ant_check";
        interrupt-parent = <&tlmm>;
        pinctrl-0 = <&ant_check_default>;
        pinctrl-names = "default";
    };
    ant_check_div {
        ant_check_div_gpio = <&tlmm 0x19 0x0>;
        compatible = "ant_check_div";
        interrupt-parent = <&tlmm>;
        pinctrl-0 = <&ant_check_div_default>;
        pinctrl-names = "default";
    };
    fpc1020 {
        compatible = "fpc,fpc1020";
        fpc,enable-on-boot;
        fpc,gpio_irq = <&tlmm 0x53 0x0>;
        fpc,gpio_rst = <&tlmm 0x68 0x0>;
        fpc,gpio_vdd_for_plsensor = <&tlmm 0x41 0x0>;
        interrupt-parent = <&tlmm>;
        interrupts = <0x53 0x0>;
        pinctrl-0 = <&msm_gpio_104>;
        pinctrl-1 = <&msm_gpio_104_output_high>;
        pinctrl-2 = <&msm_gpio_83>;
        pinctrl-names = "fpc1020_reset_reset", "fpc1020_reset_active", "fpc1020_irq_active";
        status = "ok";
        vcc_spi-supply = <&pm6125_l9>;
        vdd_ana-supply = <&pm6125_l9>;
        vdd_io-supply = <&pm6125_l9>;
    };
    goodix_fp {
        compatible = "goodix,fingerprint";
        fp-gpio-irq = <&tlmm 0x53 0x0>;
        fp-gpio-pwr = <&tlmm 0x41 0x0>;
        fp-gpio-reset = <&tlmm 0x68 0x0>;
        interrupt = <0x53 0x0>;
        interrupt-parent = <&tlmm>;
        pinctrl-0 = <&msm_gpio_104>;
        pinctrl-1 = <&msm_gpio_104_output_high>;
        pinctrl-2 = <&msm_gpio_65>;
        pinctrl-3 = <&msm_gpio_65_output_high>;
        pinctrl-names = "goodix_reset_outputlow", "goodix_reset_outputhigh", "goodix_pwr_outputlow", "goodix_pwr_outputhigh";
        status = "okay";
        vcc_ana_supply = <&pm6125_l9>;
        vcc_spi_supply = <&pm6125_l9>;
        vdd_io-supply = <&pm6125_l9>;
    };
    gpio_keys {
        compatible = "gpio-keys";
        label = "gpio-keys";
        pinctrl-0 = <&key_vol_up_default>;
        pinctrl-names = "default";
        vol_up {
            debounce-interval = <0xF>;
            gpio-key,wakeup;
            gpios = <&pm6125_gpios 0x5 0x1>;
            label = "volume_up";
            linux,can-disable;
            linux,code = <0x73>;
            linux,input-type = <0x1>;
        };
    };
    maxim_ds28e16 {
        #io-channel-cells = <0x1>;
        compatible = "maxim,ds28e16";
        label = "max_ds28e16";
        maxim,version = <0x1>;
        status = "ok";
    };
    msm_cdc_pinctrl@106 {
        #gpio-cells = <0x0>;
        compatible = "qcom,msm-cdc-pinctrl";
        pinctrl-0 = <&spkr_1_sd_n_active>;
        pinctrl-1 = <&spkr_1_sd_n_sleep>;
        pinctrl-names = "aud_active", "aud_sleep";
        status = "disable";
    };
    msm_cdc_pinctrl@92 {
        #gpio-cells = <0x0>;
        compatible = "qcom,msm-cdc-pinctrl";
        pinctrl-0 = <&wcd937x_reset_active>;
        pinctrl-1 = <&wcd937x_reset_sleep>;
        pinctrl-names = "aud_active", "aud_sleep";
    };
    onewire_gpio {
        compatible = "xiaomi,onewire_gpio";
        label = "xm_onewire";
        mi,onewire-gpio-cfg-addr = <0x96C000 0x4>;
        pinctrl-0 = <&onewire_gpio_active>;
        pinctrl-1 = <&onewire_gpio_sleep>;
        pinctrl-names = "onewire_active", "onewire_sleep";
        status = "ok";
        xiaomi,gpio_number = <0x6C>;
        xiaomi,ow_gpio = <&tlmm 0x6C 0x0>;
        xiaomi,version = <0x1>;
    };
    qcom,nopmi-chg {
        #io-channel-cells = <0x1>;
        compatible = "qcom,nopmi-chg";
        enable_sw_jeita;
        io-channel-names = "resistance_id", "shutdown_delay", "soc_decimal", "soc_decimal_rate", "fastcharge_mode", "fg_batt_id", "charge_type", "charge_enabled", "charge_ic_type", "charge_pd_active", "sc_bus_current", "charging_enabled", "sc_chip_id", "ln_bus_current", "ln_charging_enabled", "ln_chip_id", "cc_chip_id", "ds_chip_id", "ds_chip_ok", "ds_authen_result";
        io-channels = <&sm5602 0x4B &sm5602 0x9F &sm5602 0xA0 &sm5602 0xA1 &sm5602 0xA2 &sm5602 0xB1 &bq2589x 0x74 &bq2589x 0x9E &bq2589x 0xAE &bq2589x 0x4 &sc8551_standalone 0x98 &sc8551_standalone 0x76 &sc8551_standalone 0xAB &ln8000_charger 0x98 &ln8000_charger 0x76 &ln8000_charger 0xAB &rpm 0xAB &maxim_ds28e16 0xAB &maxim_ds28e16 0x8B &maxim_ds28e16 0x82>;
        jeita_temp_above_t4_cv = <0x1004>;
        jeita_temp_below_t0_cv = <0x1162>;
        jeita_temp_t0_to_t1_cv = <0x1162>;
        jeita_temp_t1_to_t1p5_cv = <0x1162>;
        jeita_temp_t1p5_to_t2_cv = <0x1162>;
        jeita_temp_t2_to_t3_cv = <0x1162>;
        jeita_temp_t3_to_t4_cv = <0x1004>;
        jeita_temp_tn1_to_t0_cv = <0x1162>;
        nopmi,thermal-mitigation = <0x5ACA30 0x5265C0 0x4C4B40 0x44AA20 0x3D0900 0x387520 0x3567E0 0x2DC6C0 0x2AB980 0x2625A0 0x1E8480 0x16E360 0xF4240 0xC3500 0x7A120 0x55730 0xC3500 0xC3500>;
        qcom,fv-max-uv = <0x432380>;
        status = "okay";
        temp_neg_10_thres = <0xFFFFFFF6>;
        temp_t0_thres = <0x0>;
        temp_t0_thres_plus_x_degree = <0x1>;
        temp_t0_to_t1_fcc = <0x3B6>;
        temp_t1_thres = <0x5>;
        temp_t1_thres_plus_x_degree = <0x6>;
        temp_t1_to_t1p5_fcc = <0x960>;
        temp_t1p5_thres = <0xA>;
        temp_t1p5_thres_plus_x_degree = <0xB>;
        temp_t1p5_to_t2_fcc = <0xF3C>;
        temp_t2_thres = <0xF>;
        temp_t2_thres_plus_x_degree = <0x11>;
        temp_t2_to_t3_fcc = <0x173E>;
        temp_t3_thres = <0x30>;
        temp_t3_thres_minus_x_degree = <0x2E>;
        temp_t3_to_t4_fcc = <0x92E>;
        temp_t4_thres = <0x3C>;
        temp_t4_thres_minus_x_degree = <0x3A>;
        temp_tn1_thres = <0xFFFFFFF6>;
        temp_tn1_thres_plus_x_degree = <0xFFFFFFF7>;
        temp_tn1_to_t0_fcc = <0x1EA>;
    };
    qcom_cp_manager {
        compatible = "qcom,cp_manager";
        io-channel-names = "present", "charging_enabled", "status", "sc_battery_present", "sc_vbus_present", "sc_battery_voltage", "sc_battery_current", "sc_battery_temperature", "sc_bus_voltage", "sc_bus_current", "sc_bus_temperature", "sc_die_temperature", "sc_alarm_status", "sc_fault_status", "sc_vbus_error_status", "sc_chip_vendor", "sc_chip_id", "input_suspend", "pd_active", "battery_charging_enabled", "charge_enabled", "ln_status", "ln_present", "ln_constant_charge_voltage", "ln_input_current_limit", "ln_model_name", "ln_charging_enabled", "ln_ti_bypass_mode_enable", "ln_ti_set_bus_protection_for_qc3", "ln_battery_present", "ln_vbus_present", "ln_battery_voltage", "ln_battery_current", "ln_battery_temperture", "ln_bus_voltage", "ln_bus_current", "ln_bus_temperature", "ln_die_temperature", "ln_alarm_status", "ln_fault_status", "ln_ti_reg_status", "ln_hv_charge_enable", "ln_vbus_error_status", "ln_chip_id", "apdo_volt", "apdo_curr";
        io-channels = <&sc8551_standalone 0x90 &sc8551_standalone 0x76 &sc8551_standalone 0x8F &sc8551_standalone 0x92 &sc8551_standalone 0x93 &sc8551_standalone 0x94 &sc8551_standalone 0x95 &sc8551_standalone 0x96 &sc8551_standalone 0x97 &sc8551_standalone 0x98 &sc8551_standalone 0x99 &sc8551_standalone 0x9A &sc8551_standalone 0x9B &sc8551_standalone 0x91 &sc8551_standalone 0x9C &sc8551_standalone 0x9D &sc8551_standalone 0xAB &nopmi_chg 0x78 &nopmi_chg 0x4 &nopmi_chg 0x76 &bq2589x 0x9E &ln8000_charger 0x8F &ln8000_charger 0x90 &ln8000_charger 0xA6 &ln8000_charger 0xAA &ln8000_charger 0xA7 &ln8000_charger 0x76 &ln8000_charger 0xA4 &ln8000_charger 0xA5 &ln8000_charger 0x92 &ln8000_charger 0x93 &ln8000_charger 0x94 &ln8000_charger 0x95 &ln8000_charger 0x96 &ln8000_charger 0x97 &ln8000_charger 0x98 &ln8000_charger 0x99 &ln8000_charger 0x9A &ln8000_charger 0x9B &ln8000_charger 0x91 &ln8000_charger 0xA8 &ln8000_charger 0xA9 &ln8000_charger 0x9C &ln8000_charger 0xAB &nopmi_chg 0xAC &nopmi_chg 0xAD>;
        status = "okay";
    };
    rpm: rt-pd-manager {
        #io-channel-cells = <0x1>;
        compatible = "richtek,rt-pd-manager";
        io-channel-names = "usb_real_type", "pd_active", "pd_voltage_min", "pd_voltage_max", "pd_current_max", "typec_cc_orientation", "pd_usb_suspend_supported", "pd_in_hard_reset", "cc_chip_id";
        io-channels = <&nopmi_chg 0xA &nopmi_chg 0x4 &nopmi_chg 0xC &nopmi_chg 0xB &nopmi_chg 0x0 &nopmi_chg 0x3 &nopmi_chg 0x1F &nopmi_chg 0x1E &rpm 0xAB>;
    };
    rx_core_clk {
        #clock-cells = <0x1>;
        compatible = "qcom,audio-ref-clk";
        qcom,codec-ext-clk-src = <0x5>;
        qcom,codec-lpass-clk-id = <0x30E>;
        qcom,codec-lpass-ext-clk-freq = <0x1588800>;
    };
    rx_npl_clk {
        #clock-cells = <0x1>;
        compatible = "qcom,audio-ref-clk";
        qcom,codec-ext-clk-src = <0x6>;
        qcom,codec-lpass-clk-id = <0x30F>;
        qcom,codec-lpass-ext-clk-freq = <0x1588800>;
    };
    si_pa_L {
        channel_num = <0x0>;
        compatible = "si,sia81xx";
        owi_mode = <0x1>;
        si,si_pa_disable_pin = <0x1>;
        si,si_pa_reset = <&tlmm 0x6A 0x0>;
        si,si_pa_type = "sia81x9";
        timer_task_hdl = <0x0>;
    };
    simtray {
        compatible = "xiaomi,simtray-status";
        status-gpio = <&tlmm 0x4F 0x0>;
    };
    thermal-message {
        board-sensor = "VIRTUAL-SENSOR";
    };
    tx_core_clk {
        #clock-cells = <0x1>;
        compatible = "qcom,audio-ref-clk";
        qcom,codec-ext-clk-src = <0x7>;
        qcom,codec-lpass-clk-id = <0x30C>;
        qcom,codec-lpass-ext-clk-freq = <0x124F800>;
    };
    tx_npl_clk {
        #clock-cells = <0x1>;
        compatible = "qcom,audio-ref-clk";
        qcom,codec-ext-clk-src = <0x8>;
        qcom,codec-lpass-clk-id = <0x30D>;
        qcom,codec-lpass-ext-clk-freq = <0x124F800>;
    };
    va_core_clk {
        #clock-cells = <0x1>;
        compatible = "qcom,audio-ref-clk";
        qcom,codec-ext-clk-src = <0x2>;
        qcom,codec-lpass-clk-id = <0x307>;
        qcom,codec-lpass-ext-clk-freq = <0x124F800>;
    };
    va_npl_clk {
        #clock-cells = <0x1>;
        compatible = "qcom,audio-ref-clk";
        qcom,codec-ext-clk-src = <0xA>;
        qcom,codec-lpass-clk-id = <0x308>;
        qcom,codec-lpass-ext-clk-freq = <0x124F800>;
    };
    vdda_usb_ss_dp_core {
        compatible = "regulator-fixed";
        enable-active-high;
        gpio = <&pm6125_gpios 0x1 0x0>;
        pinctrl-0 = <&usb_eldo9>;
        pinctrl-names = "default";
        regulator-max-microvolt = <0xD6D80>;
        regulator-min-microvolt = <0xD6D80>;
        regulator-name = "vdd_supply";
    };
    vibrator_gpio {
        compatible = "qcom,qpnp-vibrator-ldo-tz";
        pinctrl-0 = <&vib_out_gpio8_default>;
        pinctrl-names = "default";
        status = "ok";
        vib,en-gpio = <&pm6125_gpios 0x8 0x1>;
    };
    wsa_ana_clk {
        #clock-cells = <0x1>;
        compatible = "qcom,audio-ref-clk";
        qcom,codec-ext-clk-src = <0x3>;
        qcom,codec-lpass-clk-id = <0x301>;
        qcom,codec-lpass-ext-clk-freq = <0x927C00>;
        status = "disable";
    };
    xm_pd_adapter {
        adapter_name = "pd_adapter";
        compatible = "xiaomi,pd_adapter";
    };
};

&spf_core_platform {
    cdc_pri_mi2s_gpios: pri_mi2s_pinctrl {
        #gpio-cells = <0x0>;
        compatible = "qcom,msm-cdc-pinctrl";
        pinctrl-0 = <&lpi_i2s1_sck_active &lpi_i2s1_ws_active &lpi_i2s1_sd0_active &lpi_i2s1_sd1_active>;
        pinctrl-1 = <&lpi_i2s1_sck_sleep &lpi_i2s1_ws_sleep &lpi_i2s1_sd0_sleep &lpi_i2s1_sd1_sleep>;
        pinctrl-names = "aud_active", "aud_sleep";
        qcom,lpi-gpios;
    };
    cdc_sec_mi2s_gpios: sec_mi2s_pinctrl {
        #gpio-cells = <0x0>;
        compatible = "qcom,msm-cdc-pinctrl";
        pinctrl-0 = <&lpi_i2s2_sck_active &lpi_i2s2_ws_active &lpi_i2s2_sd0_active &lpi_i2s2_sd1_active>;
        pinctrl-1 = <&lpi_i2s2_sck_sleep &lpi_i2s2_ws_sleep &lpi_i2s2_sd0_sleep &lpi_i2s2_sd1_sleep>;
        pinctrl-names = "aud_active", "aud_sleep";
        qcom,lpi-gpios;
    };
    bengal_snd: sound {
        asoc-codec = <&stub_codec &bolero_cdc &wcd937x_codec>;
        asoc-codec-names = "msm-stub-codec.1", "bolero-codec", "wcd937x_codec";
        nvmem-cell-names = "adsp_variant";
        nvmem-cells = <&adsp_variant>;
        qcom,audio-routing = "AMIC1", "Analog Mic1", "AMIC1", "MIC BIAS1", "AMIC2", "Analog Mic2", "AMIC2", "MIC BIAS2", "AMIC3", "Analog Mic3", "AMIC3", "MIC BIAS3", "TX DMIC0", "Digital Mic0", "TX DMIC0", "MIC BIAS1", "TX DMIC1", "Digital Mic1", "TX DMIC1", "MIC BIAS1", "TX DMIC2", "Digital Mic2", "TX DMIC2", "MIC BIAS3", "TX DMIC3", "Digital Mic3", "TX DMIC3", "MIC BIAS3", "IN1_HPHL", "HPHL_OUT", "IN2_HPHR", "HPHR_OUT", "IN3_AUX", "AUX_OUT", "RX_TX DEC0_INP", "TX DEC0 MUX", "RX_TX DEC1_INP", "TX DEC1 MUX", "RX_TX DEC2_INP", "TX DEC2 MUX", "RX_TX DEC3_INP", "TX DEC3 MUX", "TX SWR_INPUT", "WCD_TX_OUTPUT", "VA SWR_INPUT", "VA_SWR_CLK", "VA SWR_INPUT", "WCD_TX_OUTPUT", "TX_AIF1 CAP", "VA_SWR_CLK", "TX_AIF2 CAP", "VA_SWR_CLK", "TX_AIF3 CAP", "VA_SWR_CLK";
        qcom,cdc-dmic01-gpios = <&cdc_dmic01_gpios>;
        qcom,cdc-dmic23-gpios = <&cdc_dmic23_gpios>;
        qcom,model = "bengal-idp-snd-card";
        qcom,msm-mbhc-gnd-swh = <0x1>;
        qcom,msm-mbhc-hphl-swh = <0x1>;
        qcom,msm-mbhc-usbc-audio-supported = <0x0>;
        qcom,msm-mi2s-master = <0x1 0x1 0x1 0x1>;
        qcom,msm_audio_ssr_devs = <&audio_gpr &lpi_tlmm &bolero_cdc>;
        qcom,rxtx-bolero-codec = <0x1>;
        qcom,va-bolero-codec = <0x1>;
        qcom,wcn-btfm = <0x1>;
        qcom,wsa-aux-dev-prefix = "SpkrMono";
        qcom,wsa-max-devs = <0x0>;
        si,sia81xx-aux-devs = <&si_pa_L>;
        si,sia81xx-aux-devs-prefix = "SpkrMonoL";
        si,sia81xx-max-num = <0x1>;
    };
};

&thermal_zones {
    pm6125-tz {
        cooling-maps {
            trip0_cpu0 {
                cooling-device = <&CPU0 0x7 0x7>;
                trip = <&pm6125_trip0>;
            };
            trip0_cpu4 {
                cooling-device = <&CPU4 0x6 0xFFFFFFFF>;
                trip = <&pm6125_trip0>;
            };
            trip1_cpu1 {
                cooling-device = <&cpu1_pause 0x1 0x1>;
                trip = <&pm6125_trip1>;
            };
            trip1_cpu2 {
                cooling-device = <&cpu2_pause 0x1 0x1>;
                trip = <&pm6125_trip1>;
            };
            trip1_cpu3 {
                cooling-device = <&cpu3_pause 0x1 0x1>;
                trip = <&pm6125_trip1>;
            };
            trip1_cpu4 {
                cooling-device = <&cpu4_pause 0x1 0x1>;
                trip = <&pm6125_trip1>;
            };
            trip1_cpu5 {
                cooling-device = <&cpu5_pause 0x1 0x1>;
                trip = <&pm6125_trip1>;
            };
            trip1_cpu6 {
                cooling-device = <&cpu6_pause 0x1 0x1>;
                trip = <&pm6125_trip1>;
            };
            trip1_cpu7 {
                cooling-device = <&cpu7_pause 0x1 0x1>;
                trip = <&pm6125_trip1>;
            };
        };
    };
    rf-pa1-therm-usr {
        polling-delay = <0x0>;
        polling-delay-passive = <0x0>;
        thermal-governor = "user_space";
        thermal-sensors = <&pm6125_adc_tm 0x3>;
        wake-capable-sensor;
        trips {
            active-config0 {
                hysteresis = <0x3E8>;
                temperature = <0x1E848>;
                type = "passive";
            };
        };
    };
};

&tlmm {
    bq2589x_int_default {
        config {
            bias-pull-up;
            drive-strength = <0x2>;
            input-enable;
            pins = "gpio105";
        };
        mux {
            function = "gpio";
            pins = "gpio105";
        };
    };
    bq2589x_usb_switch_default {
        config {
            bias-disable;
            drive-strength = <0x2>;
            output-low;
            pins = "gpio66";
        };
        mux {
            function = "gpio";
            pins = "gpio66";
        };
    };
    onewire_gpio_active {
        config {
            bias-pull-up;
            drive-strength = <0x2>;
            pins = "gpio108";
        };
        mux {
            function = "gpio";
            pins = "gpio108";
        };
    };
    onewire_gpio_sleep {
        config {
            bias-pull-up;
            drive-strength = <0x2>;
            pins = "gpio108";
        };
        mux {
            function = "gpio";
            pins = "gpio108";
        };
    };
    rt1711h_int_n: rt1711h_int_n {
        config {
            bias-pull-up;
            drive-strength = <0x2>;
            pins = "gpio93";
        };
        mux {
            function = "gpio";
            pins = "gpio93";
        };
    };
    sc8551_int_default {
        config {
            bias-pull-up;
            drive-strength = <0x2>;
            input-enable;
            pins = "gpio84";
        };
        mux {
            function = "gpio";
            pins = "gpio84";
        };
    };
};

&ufshc_mem {
    qcom,vddp-ref-clk-max-microamp = <0x64>;
    qcom,vddp-ref-clk-supply = <&L18A>;
    reset-gpios = <&tlmm 0x71 0x1>;
    reset-names = "rst";
    resets = <&gcc 0x4>;
    status = "ok";
    vcc-max-microamp = <0xC3500>;
    vcc-supply = <&L24A>;
    vccq2-max-microamp = <0xC3500>;
    vccq2-supply = <&L11A>;
    vdd-hba-fixed-regulator;
    vdd-hba-supply = <&gcc_ufs_phy_gdsc>;
};

&ufsphy_mem {
    compatible = "qcom,ufs-phy-qmp-v4-khaje";
    status = "ok";
    vdda-phy-max-microamp = <0x14EC4>;
    vdda-phy-supply = <&L4A>;
    vdda-pll-max-microamp = <0x477C>;
    vdda-pll-supply = <&L18A>;
};

&usb0 {
    extcon = <&rpm &eud>;
};

&usb_qmp_dp_phy {
    vdd-supply = <&vdda_usb_ss_dp_core>;
};

